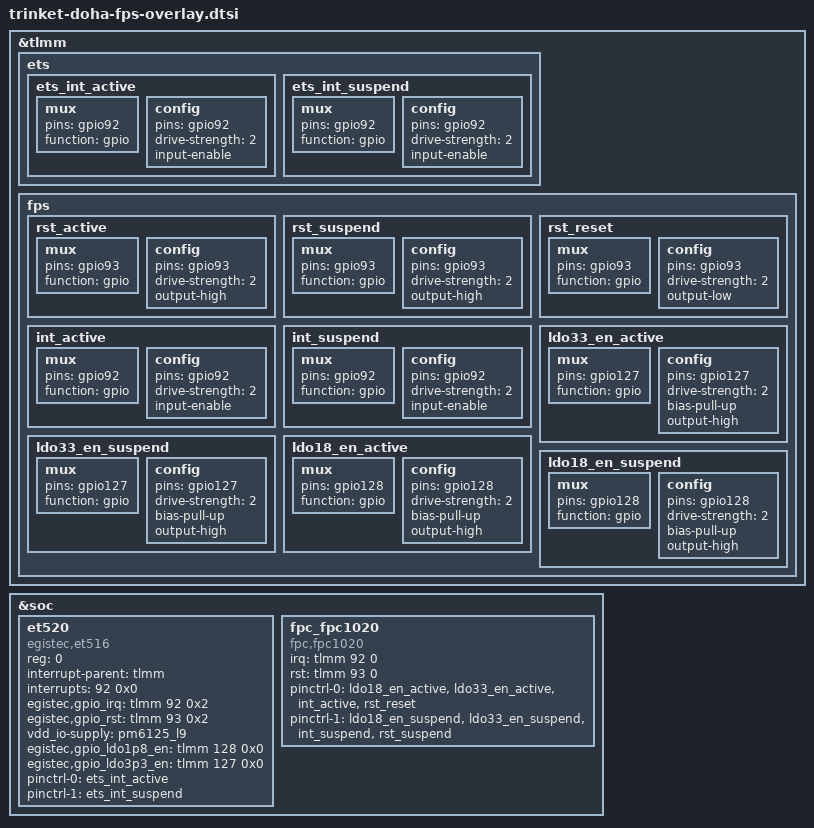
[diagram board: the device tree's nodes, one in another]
&tlmm {
	ets {
		ets_int_active: ets_int_active {
			/* INTERRUPT */
			mux {
				pins = "gpio92";
				function = "gpio";
			};

			config {
				pins = "gpio92";
				drive-strength = <2>; /* 2 MA */
				input-enable;
			};
		};
		ets_int_suspend: ets_int_suspend {
			/* INTERRUPT */
			mux {
				pins = "gpio92";
				function = "gpio";
			};

			config {
				pins = "gpio92";
				drive-strength = <2>; /* 2 MA */
				input-enable;
			};
		};
	};

	fps {
		rst_active: rst_active {
			/* RESET */
			mux {
				pins = "gpio93";
				function = "gpio";
			};
			config {
				pins = "gpio93";
				drive-strength = <2>; /* 2 MA */
				output-high;
			};
		};
		rst_suspend: rst_suspend{
			/* RESET */
			mux {
				pins = "gpio93";
				function = "gpio";
			};

			config {
				pins = "gpio93";
				drive-strength = <2>; /* 2 MA */
				output-high;
			};
		};
		rst_reset: rst_reset{
			/* RESET */
			mux {
				pins = "gpio93";
				function = "gpio";
			};

			config {
				pins = "gpio93";
				drive-strength = <2>; /* 2 MA */
				output-low;
			};
		};

		int_active: int_active {
			/* INTERRUPT */
			mux {
				pins = "gpio92";
				function = "gpio";
			};

			config {
				pins = "gpio92";
				drive-strength = <2>; /* 2 MA */
				input-enable;
			};
		};

		int_suspend: int_suspend{
			/* INTERRUPT */
			mux {
				pins = "gpio92";
				function = "gpio";
			};

			config {
				pins = "gpio92";
				drive-strength = <2>; /* 2 MA */
				input-enable;
			};
		};

		ldo33_en_active: ldo33_en_active {
			/* LDO ENABLE */
			mux {
				pins = "gpio127";
				function = "gpio";
			};

			config {
				pins = "gpio127";
				drive-strength = <2>; /* 2 MA */
				bias-pull-up; /* pull up */
				output-high;
			};
		};

		ldo33_en_suspend: ldo33_en_suspend {
			/* LDO ENABLE */
			mux {
				pins = "gpio127";
				function = "gpio";
			};

			config {
				pins = "gpio127";
				drive-strength = <2>; /* 2 MA */
				bias-pull-up; /* pull up */
				output-high;
			};
		};

		ldo18_en_active: ldo18_en_active {
			/* LDO ENABLE */
			mux {
				pins = "gpio128";
				function = "gpio";
			};

			config {
				pins = "gpio128";
				drive-strength = <2>; /* 2 MA */
				bias-pull-up; /* pull up */
				output-high;
			};
		};

		ldo18_en_suspend: ldo18_en_suspend {
			/* LDO ENABLE */
			mux {
				pins = "gpio128";
				function = "gpio";
			};

			config {
				pins = "gpio128";
				drive-strength = <2>; /* 2 MA */
				bias-pull-up; /* pull up */
				output-high;
			};
		};
	};
};

&soc {
	et520: et520 {
		compatible = "egistec,et516";
		status = "ok";
		reg = <0>;
		interrupt-parent = <&tlmm>;
		interrupts = <92 0x0>;
		egistec,gpio_irq = <&tlmm 92 0x2>;
		egistec,gpio_rst = <&tlmm 93 0x2>;
		vdd_io-supply = <&pm6125_l9>;
		egistec,gpio_ldo1p8_en = <&tlmm 128 0x0>;
		egistec,gpio_ldo3p3_en = <&tlmm 127 0x0>;
		pinctrl-names = "default", "suspend";
		pinctrl-0 = <&ets_int_active>;
		pinctrl-1 = <&ets_int_suspend>;
	};

	fpc_fpc1020 {
		compatible = "fpc,fpc1020";
		status = "ok";
		irq = <&tlmm 92 0>;
		rst = <&tlmm 93 0>;
		pinctrl-names = "default", "suspend";
		pinctrl-0 = <&ldo18_en_active &ldo33_en_active &int_active &rst_reset>;
		pinctrl-1 = <&ldo18_en_suspend &ldo33_en_suspend &int_suspend &rst_suspend>;
	};
};
